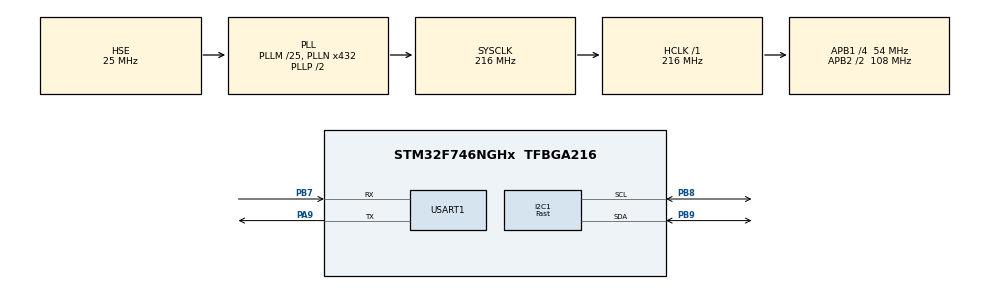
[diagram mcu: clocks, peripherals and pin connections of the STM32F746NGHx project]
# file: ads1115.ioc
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I2C1.I2C_Speed_Mode=I2C_Fast
I2C1.Timing=0x6000030D
Mcu.Family=STM32F7
Mcu.Name=STM32F746NGHx
Mcu.Package=TFBGA216
NVIC.PriorityGroup=NVIC_PRIORITYGROUP_4
PA13.Mode=Serial_Wire
PA13.Signal=SYS_JTMS-SWDIO
PA14.Mode=Serial_Wire
PA14.Signal=SYS_JTCK-SWCLK
PA9.Mode=Asynchronous
PA9.Signal=USART1_TX
PB7.Mode=Asynchronous
PB7.Signal=USART1_RX
PB8.GPIO_Pu=GPIO_NOPULL
PB8.Mode=I2C
PB8.Signal=I2C1_SCL
PB9.Mode=I2C
PB9.Signal=I2C1_SDA
PH0/OSC_IN.Mode=HSE-External-Oscillator
PH0/OSC_IN.Signal=RCC_OSC_IN
PH1/OSC_OUT.Mode=HSE-External-Oscillator
PH1/OSC_OUT.Signal=RCC_OSC_OUT
ProjectManager.HeapSize=0x200
ProjectManager.StackSize=0x400
ProjectManager.TargetToolchain=STM32CubeIDE
RCC.AHBFreq_Value=216000000
RCC.APB1CLKDivider=RCC_HCLK_DIV4
RCC.APB1Freq_Value=54000000
RCC.APB1TimFreq_Value=108000000
RCC.APB2CLKDivider=RCC_HCLK_DIV2
RCC.APB2Freq_Value=108000000
RCC.APB2TimFreq_Value=216000000
RCC.CortexFreq_Value=216000000
RCC.HCLKFreq_Value=216000000
RCC.HSE_VALUE=25000000
RCC.HSI_VALUE=16000000
RCC.LSE_VALUE=32768
RCC.PLL48CLockSelection=RCC_CLK48SOURCE_PLLSAIP
RCC.PLLI2SN=100
RCC.PLLM=25
RCC.PLLN=432
RCC.PLLQ=9
RCC.PLLSAIN=384
RCC.PLLSAIP=RCC_PLLSAIP_DIV8
RCC.PLLSAIR=5
RCC.PLLSAIRDiv=RCC_PLLSAIDIVR_8
RCC.PLLSourceVirtual=RCC_PLLSOURCE_HSE
RCC.SDMMCClockSelection=RCC_SDMMC1CLKSOURCE_CLK48
RCC.SYSCLKFreq_VALUE=216000000
RCC.SYSCLKSource=RCC_SYSCLKSOURCE_PLLCLK
RCC.USBFreq_Value=48000000
RCC.VCOOutputFreq_Value=432000000
USART1.VirtualMode-Asynchronous=VM_ASYNC
board=STM32F746G-DISCO

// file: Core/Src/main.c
/* USER CODE BEGIN Header */
/**
  ******************************************************************************
  * @file           : main.c
  * @brief          : Main program body
  ******************************************************************************
  * @attention
  *
  * Copyright (c) 2025 STMicroelectronics.
  * All rights reserved.
  *
  * This software is licensed under terms that can be found in the LICENSE file
  * in the root directory of this software component.
  * If no LICENSE file comes with this software, it is provided AS-IS.
  *
  ******************************************************************************
  */
/* USER CODE END Header */
#include "main.h"
#include "ADS1115.h"
#include <string.h>
#include <stdio.h>

I2C_HandleTypeDef hi2c1;

UART_HandleTypeDef huart1;

/* USER CODE BEGIN PV */
int __io_putchar(int ch){
	uint8_t c = (uint8_t)ch;
	HAL_UART_Transmit(&huart1, &c, 1, HAL_MAX_DELAY);
	return ch;
}
int fputc(int ch, FILE *f){
	return __io_putchar(ch);
}
/* USER CODE END PV */

void SystemClock_Config(void);
static void MX_GPIO_Init(void);
static void MX_I2C1_Init(void);
static void MX_USART1_UART_Init(void);

int main(void)
{

  /* MCU Configuration--------------------------------------------------------*/

  /* Reset of all peripherals, Initializes the Flash interface and the Systick. */
  HAL_Init();

  /* Configure the system clock */
  SystemClock_Config();

  /* Initialize all configured peripherals */
  MX_GPIO_Init();
  MX_I2C1_Init();
  MX_USART1_UART_Init();
  /* USER CODE BEGIN 2 */
  printf("\r\n--- ADS1115 example on STM32F746G-DISCO ---\r\n");

  ADS1115_Init();

  //Choose PGA
  ADS1115_PGA_t pga = ADS_PGA_2_048;
  ADS1115_DR_t dr = ADS_DR_250SPS;

  /* USER CODE END 2 */

  /* Infinite loop */
  while (1)
  {
	  int16_t raw = ADS1115_readSingleEnded(0, pga, dr, 1000);
	  float volts = ADS1115_rawToVoltage(raw, pga);
	  float ac = volts - (3.3f / 2.0f);
	  printf("raw=%6d  Vraw=%.6f V  AC=%.6f V\r\n", raw, volts, ac);
	  HAL_Delay(200);
  }
}

void SystemClock_Config(void)
{
  RCC_OscInitTypeDef RCC_OscInitStruct = {0};
  RCC_ClkInitTypeDef RCC_ClkInitStruct = {0};

  /** Configure the main internal regulator output voltage
  */
  __HAL_RCC_PWR_CLK_ENABLE();
  __HAL_PWR_VOLTAGESCALING_CONFIG(PWR_REGULATOR_VOLTAGE_SCALE1);

  /** Initializes the RCC Oscillators according to the specified parameters
  * in the RCC_OscInitTypeDef structure.
  */
  RCC_OscInitStruct.OscillatorType = RCC_OSCILLATORTYPE_HSE;
  RCC_OscInitStruct.HSEState = RCC_HSE_ON;
  RCC_OscInitStruct.PLL.PLLState = RCC_PLL_ON;
  RCC_OscInitStruct.PLL.PLLSource = RCC_PLLSOURCE_HSE;
  RCC_OscInitStruct.PLL.PLLM = 25;
  RCC_OscInitStruct.PLL.PLLN = 432;
  RCC_OscInitStruct.PLL.PLLP = RCC_PLLP_DIV2;
  RCC_OscInitStruct.PLL.PLLQ = 9;
  if (HAL_RCC_OscConfig(&RCC_OscInitStruct) != HAL_OK)
  {
    Error_Handler();
  }

  /** Activate the Over-Drive mode
  */
  if (HAL_PWREx_EnableOverDrive() != HAL_OK)
  {
    Error_Handler();
  }

  /** Initializes the CPU, AHB and APB buses clocks
  */
  RCC_ClkInitStruct.ClockType = RCC_CLOCKTYPE_HCLK|RCC_CLOCKTYPE_SYSCLK
                              |RCC_CLOCKTYPE_PCLK1|RCC_CLOCKTYPE_PCLK2;
  RCC_ClkInitStruct.SYSCLKSource = RCC_SYSCLKSOURCE_PLLCLK;
  RCC_ClkInitStruct.AHBCLKDivider = RCC_SYSCLK_DIV1;
  RCC_ClkInitStruct.APB1CLKDivider = RCC_HCLK_DIV4;
  RCC_ClkInitStruct.APB2CLKDivider = RCC_HCLK_DIV2;

  if (HAL_RCC_ClockConfig(&RCC_ClkInitStruct, FLASH_LATENCY_7) != HAL_OK)
  {
    Error_Handler();
  }
}

static void MX_I2C1_Init(void)
{

  hi2c1.Instance = I2C1;
  hi2c1.Init.Timing = 0x6000030D;
  hi2c1.Init.OwnAddress1 = 0;
  hi2c1.Init.AddressingMode = I2C_ADDRESSINGMODE_7BIT;
  hi2c1.Init.DualAddressMode = I2C_DUALADDRESS_DISABLE;
  hi2c1.Init.OwnAddress2 = 0;
  hi2c1.Init.OwnAddress2Masks = I2C_OA2_NOMASK;
  hi2c1.Init.GeneralCallMode = I2C_GENERALCALL_DISABLE;
  hi2c1.Init.NoStretchMode = I2C_NOSTRETCH_DISABLE;
  if (HAL_I2C_Init(&hi2c1) != HAL_OK)
  {
    Error_Handler();
  }

  /** Configure Analogue filter
  */
  if (HAL_I2CEx_ConfigAnalogFilter(&hi2c1, I2C_ANALOGFILTER_ENABLE) != HAL_OK)
  {
    Error_Handler();
  }

  /** Configure Digital filter
  */
  if (HAL_I2CEx_ConfigDigitalFilter(&hi2c1, 0) != HAL_OK)
  {
    Error_Handler();
  }

}

static void MX_USART1_UART_Init(void)
{

  huart1.Instance = USART1;
  huart1.Init.BaudRate = 115200;
  huart1.Init.WordLength = UART_WORDLENGTH_8B;
  huart1.Init.StopBits = UART_STOPBITS_1;
  huart1.Init.Parity = UART_PARITY_NONE;
  huart1.Init.Mode = UART_MODE_TX_RX;
  huart1.Init.HwFlowCtl = UART_HWCONTROL_NONE;
  huart1.Init.OverSampling = UART_OVERSAMPLING_16;
  huart1.Init.OneBitSampling = UART_ONE_BIT_SAMPLE_DISABLE;
  huart1.AdvancedInit.AdvFeatureInit = UART_ADVFEATURE_NO_INIT;
  if (HAL_UART_Init(&huart1) != HAL_OK)
  {
    Error_Handler();
  }

}

static void MX_GPIO_Init(void)
{

  /* GPIO Ports Clock Enable */
  __HAL_RCC_GPIOB_CLK_ENABLE();
  __HAL_RCC_GPIOA_CLK_ENABLE();
  __HAL_RCC_GPIOH_CLK_ENABLE();

}

void Error_Handler(void)
{
  __disable_irq();
  while (1)
  {
  }
}
